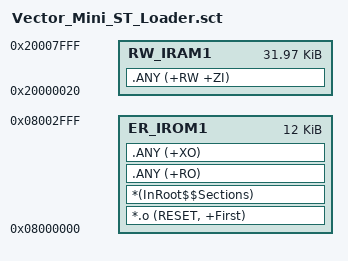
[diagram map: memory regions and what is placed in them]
; *************************************************************
; *** Scatter-Loading Description File generated by uVision ***
; *************************************************************

LR_IROM1 0x08000000 0x00003000  {    ; Loader load region (pages 0-5)
  ER_IROM1 0x08000000 0x00003000  {  ; load address = execution address
   *.o (RESET, +First)
   *(InRoot$$Sections)
   .ANY (+RO)
   .ANY (+XO)
  }
  RW_IRAM1 0x20000020 0x00007FE0  {  ; RW data (first 32 bytes reserved for boot mailbox)
   .ANY (+RW +ZI)
  }
}
